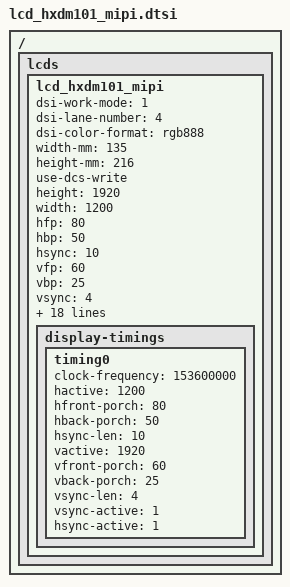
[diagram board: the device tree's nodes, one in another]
// SPDX-License-Identifier: GPL-2.0

/ { lcds: lcds {
	lcd_hxdm101_mipi: lcd_hxdm101_mipi {
		dsi-work-mode = <1>; /* video burst mode*/
		dsi-lane-number = <4>;
		dsi-color-format = "rgb888";
		width-mm = <135>;
		height-mm = <216>;
		use-dcs-write;

		/*mipi info*/
		height = <1920>;
		width = <1200>;
		hfp = <80>;
		hbp = <50>;
		hsync = <10>;
		vfp = <60>;
		vbp = <25>;
		vsync = <4>;
		fps = <60>;
		work-mode = <0>;
		rgb-mode = <3>;
		lane-number = <4>;
		phy-bit-clock = <1000000000>;
		phy-esc-clock = <76800000>;
		split-enable = <0>;
		eotp-enable = <0>;
		burst-mode = <2>;
		esd-check-enable = <0>;

		/* DSI_CMD, DSI_MODE, timeout, len, cmd */
		initial-command = [
			39 01 00 02 B0 00
			39 01 00 02 B2 50
			39 01 00 02 B0 01
			39 01 00 02 C0 00
			39 01 00 02 C1 17
			39 01 00 02 C2 01
			39 01 00 02 C3 26
			39 01 00 02 C4 00
			39 01 00 02 C5 23
			39 01 00 02 C6 11
			39 01 00 02 C7 05
			39 01 00 02 C8 07
			39 01 00 02 C9 09
			39 01 00 02 CA 0B
			39 01 00 02 CB 1B
			39 01 00 02 CC 1D
			39 01 00 02 CD 1F
			39 01 00 02 CE 21
			39 01 00 02 CF 0F
			39 01 00 02 D0 0D
			39 01 00 02 D1 00
			39 01 00 02 D2 00
			39 01 00 02 D3 00
			39 01 00 02 D4 00
			39 01 00 02 D5 18
			39 01 00 02 D6 02
			39 01 00 02 D7 26
			39 01 00 02 D8 00
			39 01 00 02 D9 23
			39 01 00 02 DA 11
			39 01 00 02 DB 06
			39 01 00 02 DC 08
			39 01 00 02 DD 0A
			39 01 00 02 DE 0C
			39 01 00 02 DF 1C
			39 01 00 02 E0 1E
			39 01 00 02 E1 20
			39 01 00 02 E2 22
			39 01 00 02 E3 10
			39 01 00 02 E4 0E
			39 01 00 02 E5 00
			39 01 00 02 E6 00
			39 01 00 02 E7 00
			39 01 00 02 B0 03
			39 01 00 02 BE 04
			39 01 00 02 B9 40
			39 01 00 02 CC 88
			39 01 00 02 C8 0C
			39 01 00 02 C9 07
			39 01 00 02 CD 01
			39 01 00 02 CA 40
			39 01 00 02 CE 1A
			39 01 00 02 CF 60
			39 01 00 02 D2 08
			39 01 00 02 D3 08
			39 01 00 02 DB 01
			39 01 00 02 D9 06
			39 01 00 02 D4 00
			39 01 00 02 D5 01
			39 01 00 02 D6 04
			39 01 00 02 D7 03
			39 01 00 02 C2 00
			39 01 00 02 C3 0E
			39 01 00 02 C4 00
			39 01 00 02 C5 0E
			39 01 00 02 DD 00
			39 01 00 02 DE 0E
			39 01 00 02 E6 00
			39 01 00 02 E7 0E
			39 01 00 02 C2 00
			39 01 00 02 C3 0E
			39 01 00 02 C4 00
			39 01 00 02 C5 0E
			39 01 00 02 DD 00
			39 01 00 02 DE 0E
			39 01 00 02 E6 00
			39 01 00 02 E7 0E
			39 01 00 02 B0 06
			39 01 00 02 C0 A5
			39 01 00 02 D5 1C
			39 01 00 02 C0 00
			39 01 00 02 B0 00
			39 01 00 02 BD 17
			39 01 00 02 BA 8F
			39 01 00 02 F9 5C
			39 01 00 02 C2 14
			39 01 00 02 C4 14
			39 01 00 02 BF 1A
			39 01 00 02 C0 11
			39 01 96 01 11
			39 01 32 01 29
		];
		sleep-in-command = [
			39 01 78 01 28
			39 01 78 01 10
		];
		sleep-out-command = [
			39 01 96 01 11
			39 01 32 01 29
		];
		read-id-command = [
			37 01 00 01 05
			14 01 00 05 fb fc fd fe ff
		];

		display-timings {
			timing0 {
				clock-frequency = <153600000>;
				hactive = <1200>;
				hfront-porch = <80>;
				hback-porch = <50>;
				hsync-len = <10>;
				vactive = <1920>;
				vfront-porch = <60>;
				vback-porch = <25>;
				vsync-len = <4>;
				vsync-active = <1>;
				hsync-active = <1>;
			};
		};
	};
};};
